# ECAP2_CTL_STS register map
Vendor: Texas Instruments
Peripheral module from a debugger description file (folder J7_AHP).
Registers are 32-bit, read-write, reset 0x0 unless marked. A register's access mark holds for its fields unless they carry their own. Offsets are as the file gives them; lines under a group give offsets from that group; [hi:lo] are bit positions; {n}, {i} and the like mark numbered series; 'fields as' and 'values as' point back to an identical list; <NAME> marks a mode.

## ECAP2_CTL_STS
0x00 CTL_STS_TSCNT
  [31:0] TSCNT — Active 32 bit Counter register which is used as the Capture time-base
0x04 CTL_STS_CNTPHS
  [31:0] CNTPHS — Counter Phase value register that can be programmed for phase Lag/Lead. This register shadows TSCNT and is loaded into TSCNT upon either a SYNCI event or S/W force via a control bit. Used to achieve Phase control sync with respect to other ECAP and EPWM time-bases.
0x08 CTL_STS_CAP1
  [31:0] CAP1 — This register can be loaded (written) by : 1. Time-Stamp (i.e. counter value) during a Capture event 2. S/W - may be useful for test purposes / initialisation 3. APRD shadow register (i.e. CAP3) when used in APWM mode
0x0C CTL_STS_CAP2
  [31:0] CAP2 — This register can be loaded (written) by : 1. Time-Stamp (i.e. counter value) during a Capture event 2. S/W - may be useful for test purposes 3. ACMP shadow register (i.e. CAP4) when used in APWM mode
0x10 CTL_STS_CAP3
  [31:0] CAP3 — In CMP mode this is a time-stamp capture register In APMW mode this is the Period Shadow (APER) register. User updates the PWM Period value via this register. In this mode CAP3 (APRD) shadows CAP1
0x14 CTL_STS_CAP4
  [31:0] CAP4 — In CMP mode this is a time-stamp capture register In APMW mode this is the Compare Shadow (ACMP) register. User updates the PWM Compare value via this register. In this mode CAP4 (ACMP) shadows CAP2
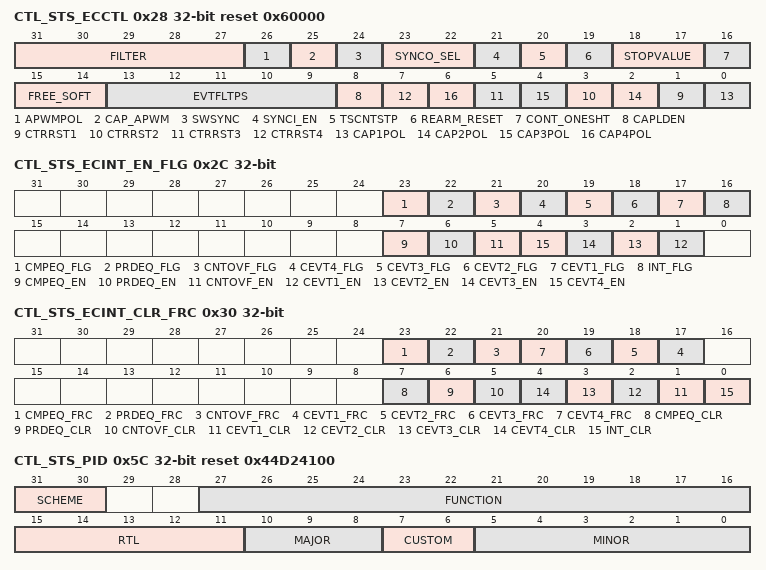
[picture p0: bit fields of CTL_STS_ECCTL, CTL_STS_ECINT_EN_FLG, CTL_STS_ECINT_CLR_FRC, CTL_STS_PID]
0x28 CTL_STS_ECCTL access not given reset 0x60000
  [31:27] FILTER ro
  [26] APWMPOL rw — APWM output polarity select: 1'b0 Output is Active High (i.e. Compare value defines High time); 1'b1 Output is Active Low (i.e. Compare value defines Low time); Note: This is applicable only in APWM operating mode
  [25] CAP_APWM rw — CAP/APWM operating mode select: 1'b0 ECAP module operates in Capture mode This mode forces the following configuration: 1- Inhibits TSCNT resets via PRD_eq event 2- Inhibits Shadow loads on CAP1 & 2 registers 3- Permits User to enable CAP1-4 register load 4- CAPx/APWMx pin operates as a Capture input* 1'b1 ECAP module operates in APWM mode This mode forces the following configuration: 1- Inhibits TSCNT resets via PRD_eq event 2- Inhibits Shadow loads on CAP1 & 2 registers 3- Permits User to enable CAP1-4 register load 4- CAPx/APWMx pin operates as a Capture input*; 1'b1 ECAP module operates in APWM mode This mode forces the following configuration: 1- Resets TSCNT on PRD_eq event (period boundary) 2- Permits Shadow loading on CAP1 & 2 registers 3- Disables loading of Time-stamps into CAP1-4 regs 4- CAPx/APWMx pin operates as a APWM output*
  [24] SWSYNC — Software forced Counter (TSCNT) sync'ing: 1'b0 Writing a Zero has no effect Reading will always return a zero; 1'b1 Writing a One will force a TSCNT shadow load of current ECAP module and any ECAP modules down-stream providing the SYNCO_SEL bits are 2'b00. After writing a one this bit returns to a zero. Note: This provides a convenient S/W method to synchronize some or all ECAP Timebases. In APWM mode the sync'ing can also be done via the PRD_eq event. (access WTC)
  [23:22] SYNCO_SEL rw — Sync-Out select: 2'b00 Select Sync-In event to be the Sync-Out signal (pass through); 2'b01 Select PRD_eq event to be the Sync-Out signal; 2'b10 DISABLE Sync Out Signal; 2'b11 DISABLE Sync Out Signal; Note: Selection PRD_eq is meaningful only in APWM mode, however can still be chosen in CAP mode if user believes it to be useful.
  [21] SYNCI_EN rw — Counter (TSCNT) Sync-In select mode: 1'b0 Disable Sync-In option 1'b1 Enable Counter (TSCNT) to be loaded from CNTPHS register upon either a SYNCI signal or a S/W force event.
  [20] TSCNTSTP rw — Counter Stop (freeze) Control: 1'b0 Counter Stopped; 1'b1 Counter Free Running
  [19] REARM_RESET — One-Shot Re-arming, i.e. Wait for stop Trigger: Writing a One Arms the One-Shot sequence, i.e.: 1. Resets the Mod4 counter to zero 2. Un-freezes the Mod4 counter 3. Enables Capture Register Loads; Writing a zero has no effect. Reading always returns a 0. Note: The RE-ARM function is valid in ONESHT or CONTINOUS mode. (access WTC)
  [18:17] STOPVALUE rw — Stop value for One-Shot mode: This is the number (between 1-4) of Captures allowed to occur before the CAP(1-4) registers are frozen, i.e.Capture sequence is stopped. 2'b00 Stop after Capture Event 1; 2'b01 Stop after Capture Event 2; 2'b10 Stop after Capture Event 3; 2'b11 Stop after Capture Event 4; Notes: [1] STOPVALUE is compared to Mod4 counter, when equal, 2 actions occur: 1- Mod4 Counter is stopped (frozen) 2- Capture Register Loads are inhibited [2] In one shot mode, further interrupt events are blocked until we re-arm, once the number of events captured has been reached.
  [16] CONT_ONESHT rw — Continuous or Oneshot mode control: (applicable only in Capture mode) 1'b0 Operate in Continuous mode 1'b1 Operate in One-Shot mode
  [15:14] FREE_SOFT rw — Emulation Control 2'b00 TSCNT Counter stops immediately on emulation suspend; 2'b01 TSCNT Counter runs until = 0; 2'b1X TSCNT Counter is unaffected by emulation suspend (Run Free)
  [13:9] EVTFLTPS rw — Event Filter prescale select: 5'b00000 divide by 1 (i.e. no prescale, by-pass the prescaler); 5'b00001 divide by 2; 5'b00010 divide by 4; 5'b00011 divide by 6; 5'b00100 divide by 8; 5'b00101 divide by 10; . . . . .; 5'b11110 divide by 60; 5'b11111 divide by 62
  [8] CAPLDEN rw — Enable Loading of CAP1-4 registers on a Capture Event: 1'b0 Disable CAP1-4 register loads at capture Event time; 1'b1 Enable CAP1-4 register loads at capture Event time
  [2n-1] CTRRST{n} rw (n=1..4) — Counter Reset on Capture Event {n}: 1'b0 Do Not reset Counter on Capture Event {n} (absolute time stamp); 1'b1 Reset Counter after Event {n} time-stamp has been captured (used in Difference mode operation)
  [2n-2] CAP{n}POL rw (n=1..4) — Capture Event {n} Polarity select: 1'b0 Capture event {n} triggered on a Rising Edge (FE); 1'b1 Capture event {n} triggered on a Falling Edge (FE)
0x2C CTL_STS_ECINT_EN_FLG access per field
  [23] CMPEQ_FLG ro — Compare Equal Status Flag: Reading a 1 on this bit indicates the Counter (TSCNT) reached the Compare register value (ACMP) Reading a 0 indicates no event occurred Note: This flag is only active in APWM mode.
  [22] PRDEQ_FLG ro — Period Equal Status Flag: Reading a 1 on this bit indicates the Counter (TSCNT) reached the Period register value (APER) and was reset. Reading a 0 indicates no event occurred Notes: This flag is only active in APWM mode.
  [21] CNTOVF_FLG ro — Counter Overflow Status Flag: Reading a 1 on this bit indicates the Counter (TSCNT) has made the transition from 0xFFFFFFFF 0x00000000 Reading a 0 indicates no event occurred. Note: This flag is active in CAP & APWM mode.
  [20] CEVT4_FLG ro — Capture Event 4 Status Flag: Reading a 1 on this bit indicates the fourth event occurred at ECAPx pin. Reading a 0 indicates no event occurred. Note: This flag is only active in CAP mode.
  [19] CEVT3_FLG ro — Capture Event 3 Status Flag: Reading a 1 on this bit indicates the third event occurred at ECAPx pin. Reading a 0 indicates no event occurred. Note: This flag is only active in CAP mode.
  [18] CEVT2_FLG ro — Capture Event 2 Status Flag: Reading a 1 on this bit indicates the second event occurred at ECAPx pin. Reading a 0 indicates no event occurred. Note: This flag is only active in CAP mode.
  [17] CEVT1_FLG ro — Capture Event 1 Status Flag: Reading a 1 on this bit indicates the first event occurred at ECAPx pin. Reading a 0 indicates no event occurred. Note: This flag is only active in CAP mode.
  [16] INT_FLG ro — Global Interrupt Status Flag: Reading a 1 on this bit indicates that an interrupt was generated from one of the following events. Reading a 0 indicates no interrupt generated.
  [7] CMPEQ_EN rw — Compare Equal Interrupt Enable: 1'b0 Disabled Compare Equal as an Interrupt source; 1'b1 Enable Compare Equal as an Interrupt source
  [6] PRDEQ_EN rw — Period Equal Interrupt Enable: 1'b0 Disabled Period Equal as an Interrupt source; 1'b1 Enable Period Equal as an Interrupt source
  [5] CNTOVF_EN rw — Counter Overflow Interrupt Enable: 1'b0 Disabled Counter Overflow as an Interrupt source; 1'b1 Enable Counter Overflow as an Interrupt source
  [n] CEVT{n}_EN rw (n=1..4) — Capture Event {n} Interrupt Enable: 1'b0 Disabled Capture Event {n} as an Interrupt source: 1'b1 Enable Capture Event {n} as an Interrupt source
0x30 CTL_STS_ECINT_CLR_FRC access not given
  [23] CMPEQ_FRC — Force Compare Equal: Writing a 1 to this bit will set the CMPEQ flag bit. Writing of 0 will be ignored. Always reads back a 0. (access W1TS)
  [22] PRDEQ_FRC — Force Period Equal: Writing a 1 to this bit will set the PRDEQ flag bit. Writing of 0 will be ignored. Always reads back a 0. (access W1TS)
  [21] CNTOVF_FRC — Force Counter Overflow: Writing a 1 to this bit will set the CNTOVF flag bit. Writing of 0 will be ignored. Always reads back a 0. (access W1TS)
  [n+16] CEVT{n}_FRC (n=1..4) — Force Capture Event {n}: Writing a 1 to this bit will set the CEVT{n} flag bit. Writing of 0 will be ignored. Always reads back a 0. (access W1TS)
  [7] CMPEQ_CLR — Compare Equal Status Flag: Writing a 1 will clear the CMPEQ flag condition. Writing a 0 will have no effect. Always reads back a 0. (access W1TC)
  [6] PRDEQ_CLR — Period Equal Status Flag: Writing a 1 will clear the PRDEQ flag condition. Writing a 0 will have no effect. Always reads back a 0. (access W1TC)
  [5] CNTOVF_CLR — Counter Overflow Status Flag: Writing a 1 will clear the CNTOVF flag condition. Writing a 0 will have no effect. Always reads back a 0. (access W1TC)
  [n] CEVT{n}_CLR (n=1..4) — Capture Event {n} Status Flag: Writing a 1 will clear the CEVT{n} flag condition. Writing a 0 will have no effect. Always reads back a 0. (access W1TC)
  [0] INT_CLR — Global Interrupt Clear Flag: Writing a 1 will clear the INT flag and enable further interrupts to be generated if any of the event flags are set to 1. Writing a 0 will have no effect. Always reads back a 0. (access W1TC)
0x5C CTL_STS_PID ro reset 0x44D24100
  [31:30] SCHEME, [27:16] FUNCTION, [15:11] RTL, [10:8] MAJOR, [7:6] CUSTOM, [5:0] MINOR
